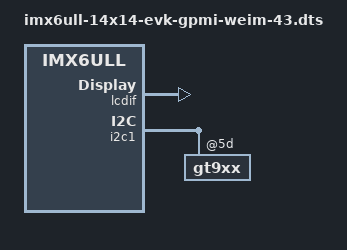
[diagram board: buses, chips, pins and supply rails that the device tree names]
/*
 * Copyright (C) 2016 Freescale Semiconductor, Inc.
 *
 * This program is free software; you can redistribute it and/or modify
 * it under the terms of the GNU General Public License version 2 as
 * published by the Free Software Foundation.
 */

#include "imx6ull-14x14-evk.dts"

&lcdif {
	pinctrl-names = "default";
	pinctrl-0 = <&pinctrl_lcdif_dat
		     &pinctrl_lcdif_ctrl>;
	display = <&display0>;
	status = "okay";

	display0: display@0 {
		bits-per-pixel = <16>;
		bus-width = <24>;

		display-timings {
			native-mode = <&timing0>;

			timing0: timing0 {
			mode_name = "TFT43AB";
			clock-frequency = <9000000>;
			hactive = <480>;
			vactive = <272>;
			hfront-porch = <8>;
			hback-porch = <2>;
			hsync-len = <41>;
			vback-porch = <4>;
			vfront-porch = <4>;
			vsync-len = <10>;

			hsync-active = <0>;
			vsync-active = <0>;
			de-active = <1>;
			pixelclk-active = <0>;
			};
		};
	};
};

&i2c1 {

	gt9xx@5d {
		touchscreen-size-x = <480>;
		touchscreen-size-y = <272>;
	};
};
